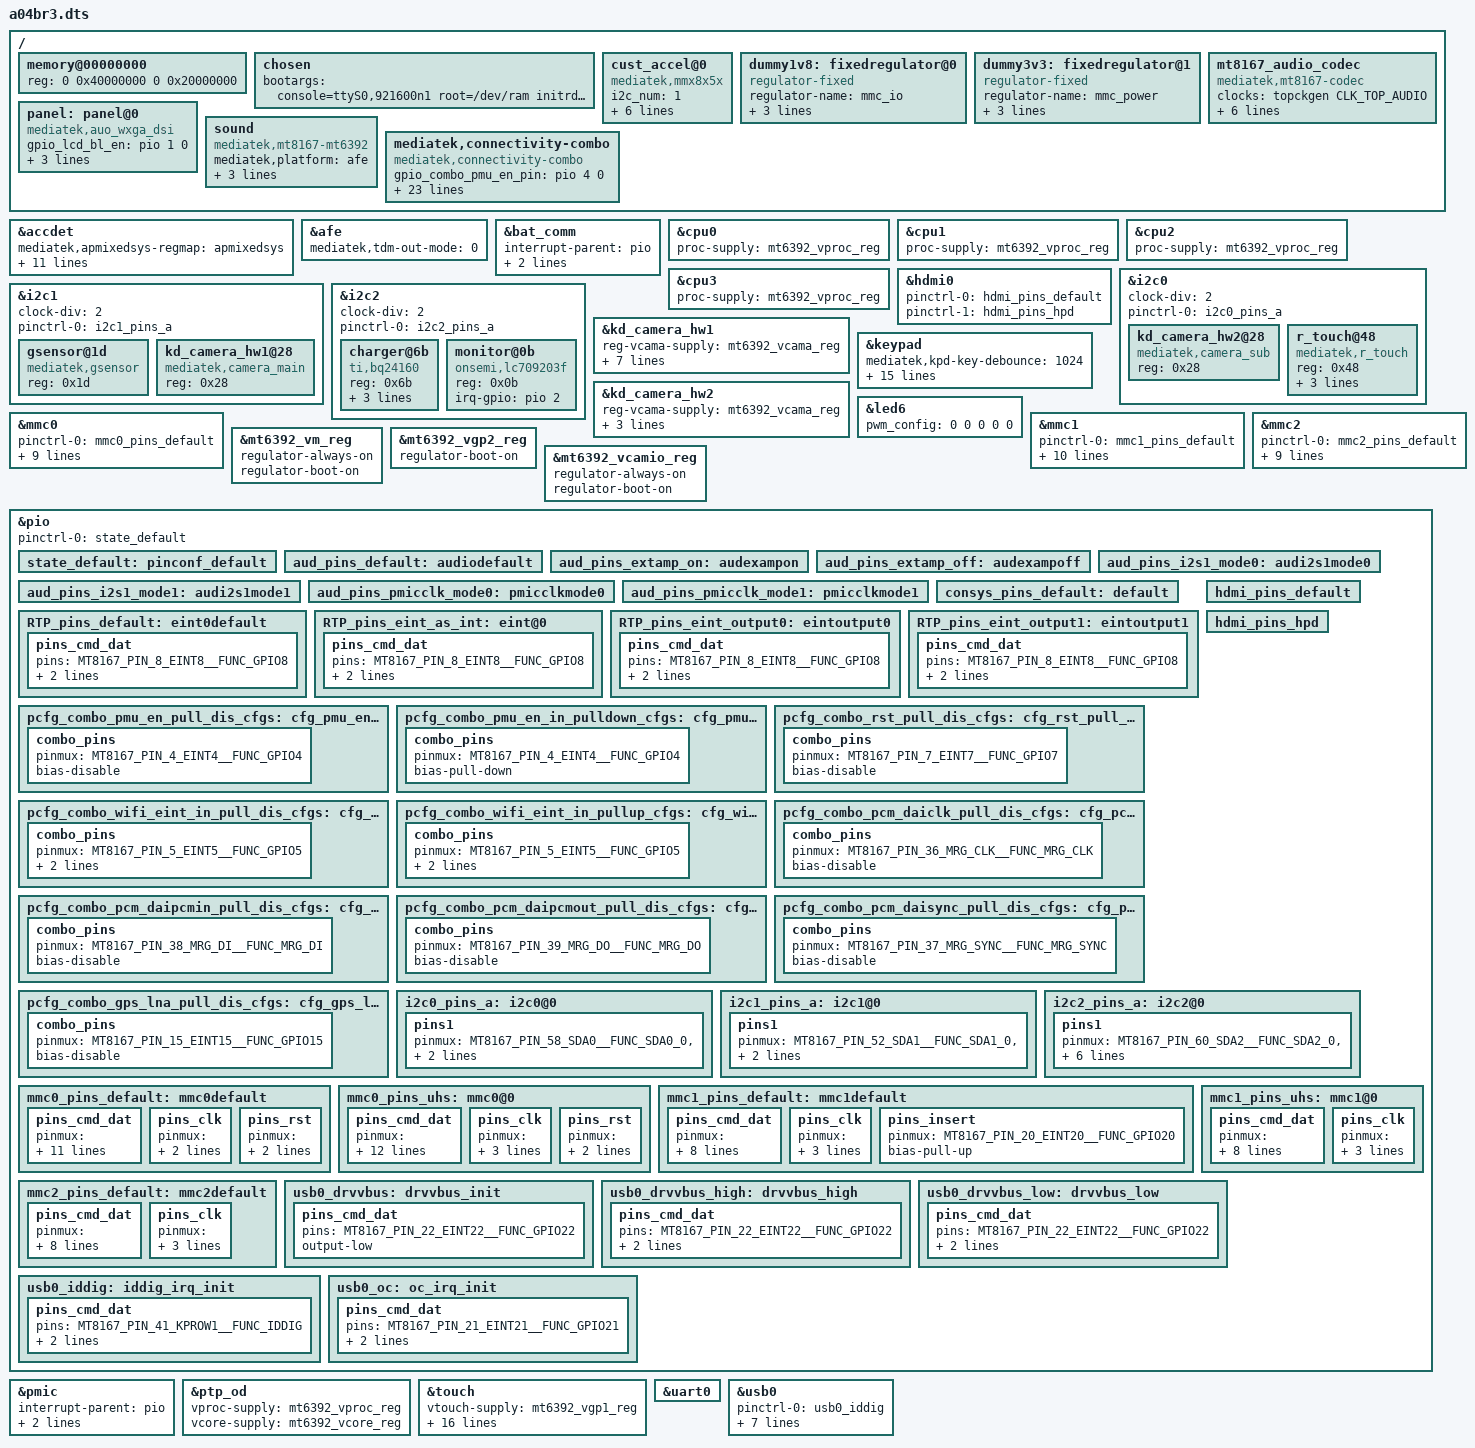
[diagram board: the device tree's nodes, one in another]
/*
 * Copyright (c) 2014-2015 MediaTek Inc.
 *
 * This program is free software; you can redistribute it and/or modify
 * it under the terms of the GNU General Public License version 2 as
 * published by the Free Software Foundation.
 *
 * This program is distributed in the hope that it will be useful,
 * MERCHANTABILITY or FITNESS FOR A PARTICULAR PURPOSE.  See the
 * GNU General Public License for more details.
 */
/*
 * Copyright (C) 2017 SANYO Techno Solutions Tottori Co., Ltd.
 *
 * Changelog:
 *
 * 2018-Feb:  Modify device setting.
 *
 */

/dts-v1/;

#include "mt8167.dtsi"
#include "mt6392.dtsi"

/ {
	memory@00000000 {
		device_type = "memory";
		reg = <0 0x40000000 0 0x20000000>;
	};

	/* chosen */
	chosen {
		bootargs = "console=ttyS0,921600n1 root=/dev/ram initrd=0x44000200,0x200000";
	};

/* sensor standardization */
	cust_accel@0 {
		compatible = "mediatek,mmx8x5x";
/*		compatible = "mediatek,lis2dh";*/
		i2c_num = <1>;
		i2c_addr = <0x1d 0 0 0>;
/*		i2c_addr = <0x18 0 0 0>;*/
		direction = <7>;
		power_id = <0xffff>;
		power_vol = <0>;
		firlen = <0>;
		is_batch_supported = <0>;
	};
/* sensor gpio standization */

	dummy1v8: fixedregulator@0 {
		compatible = "regulator-fixed";
		regulator-name = "mmc_io";
		regulator-min-microvolt = <1800000>;
		regulator-max-microvolt = <1800000>;
		regulator-always-on;
	};

	dummy3v3: fixedregulator@1 {
		compatible = "regulator-fixed";
		regulator-name = "mmc_power";
		regulator-min-microvolt = <3300000>;
		regulator-max-microvolt = <3300000>;
		regulator-always-on;
	};

	mt8167_audio_codec: mt8167_audio_codec {
		compatible = "mediatek,mt8167-codec";
		clocks = <&topckgen CLK_TOP_AUDIO>;
		clock-names = "bus";
		mediatek,afe-regmap = <&afe>;
		mediatek,apmixedsys-regmap = <&apmixedsys>;
		mediatek,pwrap-regmap = <&pwrap>;
		mediatek,speaker-mode = <0>; /* 0(CLASSD) 1(CLASSAB) */
		mediatek,dmic-wire-mode = <1>; /* 0(ONE_WIRE) 1(TWO_WIRE) */
		mediatek,headphone-cap-sel = <1>; /* 0(10UF) 1(22UF) 2(33UF) 3(47UF) */
	};

	panel: panel@0 {
		compatible = "mediatek,auo_wxga_dsi";
		gpio_lcd_bl_en = <&pio 1 0>;
		gpio_lcd_stby = <&pio 67 0>;
		gpio_lcd_rst = <&pio 66 0>;
		reg-lcm-supply = <&mt6392_vgp2_reg>;
		status = "okay";
	};

	sound: sound {
		compatible = "mediatek,mt8167-mt6392";
		mediatek,platform = <&afe>;
		pinctrl-names = "default", "extamp_on", "extamp_off";
		pinctrl-0 = <&aud_pins_default>;
		pinctrl-1 = <&aud_pins_extamp_on>;
		pinctrl-2 = <&aud_pins_extamp_off>;
		status = "okay";
	};

	mediatek,connectivity-combo {
		compatible = "mediatek,connectivity-combo";
		gpio_combo_pmu_en_pin = <&pio 4 0>;	/* GPIO_COMBO_PMU_EN_PIN */
		gpio_combo_rst_pin = <&pio 7 0>;		/* GPIO_COMBO_RST_PIN pin */
		gpio_wifi_eint_pin = <&pio 5 0>;		/* GPIO_WIFI_EINT_PIN */
		gpio_pcm_daiclk_pin = <&pio 36 0>;		/* GPIO_PCM_DAICLK_PIN */
		gpio_pcm_daipcmin_pin = <&pio 38 0>;	/* GPIO_PCM_DAIPCMIN_PIN */
		gpio_pcm_daipcmout_pin = <&pio 39 0>;	/* GPIO_PCM_DAIPCMOUT_PIN */
		gpio_pcm_daisync_pin = <&pio 37 0>;		/* GPIO_PCM_DAISYNC_PIN */
		gpio_gps_lna_pin = <&pio 15 0>;			/* GPIO_GPS_LNA_PIN */
		pinctrl-names = "gpio_pmu_en_pull_dis",
			"gpio_pmu_en_in_pulldown",
			"gpio_rst_pull_dis",
			"gpio_wifi_eint_in_pull_dis",
			"gpio_wifi_eint_in_pullup",
			"gpio_pcm_daiclk_pull_dis",
			"gpio_pcm_daipcmin_pull_dis",
			"gpio_pcm_daipcmout_pull_dis",
			"gpio_pcm_daisync_pull_dis",
			"gpio_gps_lna_pull_dis";
		pinctrl-0 = <&pcfg_combo_pmu_en_pull_dis_cfgs>;
		pinctrl-1 = <&pcfg_combo_pmu_en_in_pulldown_cfgs>;
		pinctrl-2 = <&pcfg_combo_rst_pull_dis_cfgs>;
		pinctrl-3 = <&pcfg_combo_wifi_eint_in_pull_dis_cfgs>;
		pinctrl-4 = <&pcfg_combo_wifi_eint_in_pullup_cfgs>;
		pinctrl-5 = <&pcfg_combo_pcm_daiclk_pull_dis_cfgs>;
		pinctrl-6 = <&pcfg_combo_pcm_daipcmin_pull_dis_cfgs>;
		pinctrl-7 = <&pcfg_combo_pcm_daipcmout_pull_dis_cfgs>;
		pinctrl-8 = <&pcfg_combo_pcm_daisync_pull_dis_cfgs>;
		pinctrl-9 = <&pcfg_combo_gps_lna_pull_dis_cfgs>;
		interrupt-parent = <&pio>;
		interrupts = < 5 IRQ_TYPE_LEVEL_LOW >;	/* WIFI EINT num is 1 active low level-sensitive */
	};
};

&accdet {
	mediatek,apmixedsys-regmap = <&apmixedsys>;
	interrupts-extended = <&sysirq GIC_SPI 152 IRQ_TYPE_LEVEL_LOW>,
				<&pio 19 IRQ_TYPE_LEVEL_LOW>;
	interrupts = <19 IRQ_TYPE_LEVEL_LOW>;
	eint-debounce = <512000>;
	accdet-gpio = <&pio 19 0>;
	accdet-mic-vol = <0>;
	headset-mode-setting = <0x500 0x500 1 0x1f0 0x800 0x800 0x40>;
	accdet-plugout-debounce = <20>;
	/*1:ACC mode, 2:low cost without in bias, 6:low cost with in bias*/
	accdet-mic-mode = <1>;
	status = "okay";
};

&afe {
	/* 0(HDMI) 1(I2S) 2(TDM) */
	mediatek,tdm-out-mode = <0>;
};

&bat_comm {
	interrupt-parent = <&pio>;
	interrupts = <11 IRQ_TYPE_EDGE_RISING>;
	chgled-gpio = <&pio 10 0>;
};


&cpu0 {
	proc-supply = <&mt6392_vproc_reg>;
};

&cpu1 {
	proc-supply = <&mt6392_vproc_reg>;
};

&cpu2 {
	proc-supply = <&mt6392_vproc_reg>;
};

&cpu3 {
	proc-supply = <&mt6392_vproc_reg>;
};

&hdmi0 {
	pinctrl-names = "default", "hdmi_hpd";
	pinctrl-0 = <&hdmi_pins_default>;
	pinctrl-1 = <&hdmi_pins_hpd>;
	status = "okay";
};

&i2c0 {
	clock-div = <2>;
	pinctrl-names = "default";
	pinctrl-0 = <&i2c0_pins_a>;
	status = "okay";

	kd_camera_hw2@28 {
		compatible = "mediatek,camera_sub";
		reg = <0x28>;
	};

	r_touch@48 {
		compatible = "mediatek,r_touch";
		reg = <0x48>;
		interrupt-parent = <&pio>;
		interrupts = <8 IRQ_TYPE_EDGE_FALLING>;
		int-gpio = <&pio 8 0>;

	/*	digipen-gpio = <&pio 0 0>;*/
	};

/*
	wacom_touch@9 {
		compatible = "wacom,i2c";
		reg = <0x09>;
		interrupt-parent = <&pio>;
		interrupts = <3 IRQ_TYPE_EDGE_FALLING>;
		int-gpio = <&pio 3 0>;
		rst-gpio = <&pio 14 0>;
		power-gpio = <&pio 51 0>;
		wacom,swap_xy = <1>;
		wacom,invert_x = <0>;
		wacom,invert_y = <1>;
	};
*/
};

&i2c1 {
	clock-div = <2>;
	pinctrl-names = "default";
	pinctrl-0 = <&i2c1_pins_a>;
	status = "okay";

	gsensor@1d {
		compatible = "mediatek,gsensor";
		reg = <0x1d>;
/*		reg = <0x18>;*/
	};

	kd_camera_hw1@28 {
		compatible = "mediatek,camera_main";
		reg = <0x28>;
	};
};

&i2c2 {
	clock-div = <2>;
	pinctrl-names = "default";
	pinctrl-0 = <&i2c2_pins_a>;
	status = "okay";

	charger@6b {
		compatible = "ti,bq24160";
		reg      = <0x6b>;
		ena-gpio = <&pio 9 0>;
		acdet-gpio = <&pio 35 0>;
		usbdet-gpio = <&pio 34 0>;
	};

	monitor@0b {
		compatible = "onsemi,lc709203f";
		reg      = <0x0b>;
		irq-gpio = <&pio 2 0>;
	};
};

/* Main Cam */
&kd_camera_hw1 {
	reg-vcama-supply = <&mt6392_vcama_reg>;		/* AVDD */
	reg-vcamd-supply = <&mt6392_vcamd_reg>;		/* DVDD */
	reg-vcamio-supply = <&mt6392_vcamio_reg>;	/* DOVDD */
	reg-vcamaf-supply = <&mt6392_vcamaf_reg>;	/* AFVDD */

	cam0_rst = <&pio 49 0>;
	cam0_pdn = <&pio 48 0>;
	cam1_rst = <&pio 100 0>;
	cam1_pdn = <&pio 101 0>;

	status = "okay";
};

/* Sub Cam */
&kd_camera_hw2{
	reg-vcama-supply = <&mt6392_vcama_reg>;		/* AVDD */
	reg-vcamd-supply = <&mt6392_vcamd_reg>;		/* DVDD */
	reg-vcamio-supply = <&mt6392_vcamio_reg>;	/* DOVDD */
	reg-vcamaf-supply = <&mt6392_vcamaf_reg>;	/* AFVDD */

	status = "okay";
};

&keypad {
	mediatek,kpd-key-debounce = <1024>;
	mediatek,kpd-sw-pwrkey = <116>;
	mediatek,kpd-hw-pwrkey = <8>;
	mediatek,kpd-sw-rstkey  = <0>;
	mediatek,kpd-hw-rstkey = <17>;
	mediatek,kpd-use-extend-type = <0>;
	/*HW Keycode [0~71] -> Linux Keycode*/
	mediatek,kpd-hw-map-num = <72>;
	mediatek,kpd-hw-init-map = <115 102 0 0 0 0 0 0 0 0 0 0 0 0 0 0 0 0 0 0 0 0 0 0
			0 0 0 0 0 0 0 0 0 0 0 0 0 0 0 0 0 0 0 0 0 0 0 0
			0 0 0 0 0 0 0 0 0 0 0 0 0 0 0 0 0 0 0 0 0 0 0 0 >;
	mediatek,kpd-pwrkey-eint-gpio = <0>;
	mediatek,kpd-pwkey-gpio-din  = <0>;
	mediatek,kpd-hw-dl-key0 = <0>;
	mediatek,kpd-hw-dl-key1 = <17>;
	mediatek,kpd-hw-dl-key2 = <8>;
	mediatek,kpd-hw-recovery-key = <17>;
	mediatek,kpd-hw-factory-key  = <0>;
};

&led6 {
	pwm_config = <0 0 0 0 0>;
};

&mmc0 {
	pinctrl-names = "default", "state_uhs";
	pinctrl-0 = <&mmc0_pins_default>;
	pinctrl-1 = <&mmc0_pins_uhs>;
	status = "okay";
	bus-width = <8>;
	max-frequency = <200000000>;
	cap-mmc-highspeed;
	mmc-hs200-1_8v;
	cap-mmc-hw-reset;
	vmmc-supply = <&mt6392_vemc3v3_reg>;
	vqmmc-supply = <&mt6392_vio18_reg>;
	non-removable;
};

&mmc1 {
	pinctrl-names = "default", "state_uhs";
	pinctrl-0 = <&mmc1_pins_default>;
	pinctrl-1 = <&mmc1_pins_uhs>;
	status = "okay";
	bus-width = <4>;
	max-frequency = <200000000>;
	cap-sd-highspeed;
	sd-uhs-sdr50;
	sd-uhs-sdr104;
	cd-gpios = <&pio 20 0>;
	cd_level = <1>;
	vmmc-supply = <&mt6392_vmch_reg>;
	vqmmc-supply = <&mt6392_vmc_reg>;
};

&mmc2 {
	pinctrl-names = "default", "state_uhs";
	pinctrl-0 = <&mmc2_pins_default>;
	status = "okay";
	clk_src = <2>;
	host_function = <2>;
	bus-width = <4>;
	max-frequency = <200000000>;
	cap-sd-highspeed;
	sd-uhs-sdr12;
	sd-uhs-sdr25;
	sd-uhs-sdr50;
	sd-uhs-sdr104;
};

&mt6392_vm_reg {
	regulator-always-on;
	regulator-boot-on;
};

&mt6392_vgp2_reg {
	regulator-boot-on;
};

&mt6392_vcamio_reg {
	regulator-always-on;
	regulator-boot-on;
};


&pio {
	pinctrl-names = "default";
	pinctrl-0 = <&state_default>;

	state_default:pinconf_default {
	};

	aud_pins_default: audiodefault {
	};

	aud_pins_extamp_on: audexampon {
	};

	aud_pins_extamp_off: audexampoff {
	};

	aud_pins_i2s1_mode0: audi2s1mode0 {
	};

	aud_pins_i2s1_mode1: audi2s1mode1 {
	};

	aud_pins_pmicclk_mode0: pmicclkmode0 {
	};

	aud_pins_pmicclk_mode1: pmicclkmode1 {
	};

	/* CONSYS GPIO Settings - Start */
	consys_pins_default: default {

	};
	/* CONSYS GPIO Settings - End */

	RTP_pins_default: eint0default {
		pins_cmd_dat {
			pins = <MT8167_PIN_8_EINT8__FUNC_GPIO8>;
			slew-rate = <0>;
			bias-disable;
		};
	};

	RTP_pins_eint_as_int: eint@0 {
		pins_cmd_dat {
			pins = <MT8167_PIN_8_EINT8__FUNC_GPIO8>;
			slew-rate = <0>;
			bias-disable;
		};
	};

	RTP_pins_eint_output0: eintoutput0 {
		pins_cmd_dat {
			pins = <MT8167_PIN_8_EINT8__FUNC_GPIO8>;
			slew-rate = <1>;
			output-low;
		};
	};

	RTP_pins_eint_output1: eintoutput1 {
		pins_cmd_dat {
			pins = <MT8167_PIN_8_EINT8__FUNC_GPIO8>;
			slew-rate = <1>;
			output-high;
		};
	};

	/* ++++++ Connectivity GPIO configs ++++++ */
	pcfg_combo_pmu_en_pull_dis_cfgs:cfg_pmu_en_pull_dis {
		combo_pins {
			pinmux = <MT8167_PIN_4_EINT4__FUNC_GPIO4>;
			bias-disable;
		};
	};

	pcfg_combo_pmu_en_in_pulldown_cfgs:cfg_pmu_en_in_pulldown {
		combo_pins {
			pinmux = <MT8167_PIN_4_EINT4__FUNC_GPIO4>;
			bias-pull-down;
		};
	};

	pcfg_combo_rst_pull_dis_cfgs:cfg_rst_pull_dis {
		combo_pins {
			pinmux = <MT8167_PIN_7_EINT7__FUNC_GPIO7>;
			bias-disable;
		};
	};

	pcfg_combo_wifi_eint_in_pull_dis_cfgs:cfg_wifi_eint_in_pull_dis {
		combo_pins {
			pinmux = <MT8167_PIN_5_EINT5__FUNC_GPIO5>;
			slew-rate = <0>;
			bias-disable;
		};
	};
	pcfg_combo_wifi_eint_in_pullup_cfgs:cfg_wifi_eint_in_pullup {
		combo_pins {
			pinmux = <MT8167_PIN_5_EINT5__FUNC_GPIO5>;
			slew-rate = <0>;
			bias-pull-up = <00>;
		};
	};

	pcfg_combo_pcm_daiclk_pull_dis_cfgs:cfg_pcm_daiclk_pull_dis {
		combo_pins {
			pinmux = <MT8167_PIN_36_MRG_CLK__FUNC_MRG_CLK>;
			bias-disable;
		};
	};

	pcfg_combo_pcm_daipcmin_pull_dis_cfgs:cfg_pcm_daipcmin_pull_dis {
		combo_pins {
			pinmux = <MT8167_PIN_38_MRG_DI__FUNC_MRG_DI>;
			bias-disable;
		};
	};

	pcfg_combo_pcm_daipcmout_pull_dis_cfgs:cfg_pcm_daipcmout_pull_dis {
		combo_pins {
			pinmux = <MT8167_PIN_39_MRG_DO__FUNC_MRG_DO>;
			bias-disable;
		};
	};

	pcfg_combo_pcm_daisync_pull_dis_cfgs:cfg_pcm_daisync_pull_dis {
		combo_pins {
			pinmux = <MT8167_PIN_37_MRG_SYNC__FUNC_MRG_SYNC>;
			bias-disable;
		};
	};

	pcfg_combo_gps_lna_pull_dis_cfgs:cfg_gps_lna_pull_dis {
		combo_pins {
			pinmux = <MT8167_PIN_15_EINT15__FUNC_GPIO15>;
			bias-disable;
		};
	};

	/* ------ Connectivity GPIO configs ------ */


	hdmi_pins_default: hdmi_pins_default {
	};

	hdmi_pins_hpd: hdmi_pins_hpd {
	};

	i2c0_pins_a: i2c0@0 {
		pins1 {
			pinmux = <MT8167_PIN_58_SDA0__FUNC_SDA0_0>,
				 <MT8167_PIN_59_SCL0__FUNC_SCL0_0>;
			bias-disable;
		};
	};

	i2c1_pins_a: i2c1@0 {
		pins1 {
			pinmux = <MT8167_PIN_52_SDA1__FUNC_SDA1_0>,
				 <MT8167_PIN_53_SCL1__FUNC_SCL1_0>;
			bias-disable;
		};
	};

	i2c2_pins_a: i2c2@0 {
		pins1 {
			pinmux = <MT8167_PIN_60_SDA2__FUNC_SDA2_0>,
				 <MT8167_PIN_61_SCL2__FUNC_SCL2_0>,
				 <MT8167_PIN_3_EINT3__FUNC_GPIO3>,
				 <MT8167_PIN_9_EINT9__FUNC_GPIO9>,
				 <MT8167_PIN_10_EINT10__FUNC_GPIO10>,
				 <MT8167_PIN_11_EINT11__FUNC_GPIO11>;
			bias-disable;
		};
	};

	mmc0_pins_default: mmc0default {
		pins_cmd_dat {
			pinmux = <MT8167_PIN_120_MSDC0_DAT0__FUNC_MSDC0_DAT0>,
				<MT8167_PIN_119_MSDC0_DAT1__FUNC_MSDC0_DAT1>,
				<MT8167_PIN_118_MSDC0_DAT2__FUNC_MSDC0_DAT2>,
				<MT8167_PIN_117_MSDC0_DAT3__FUNC_MSDC0_DAT3>,
				<MT8167_PIN_113_MSDC0_DAT4__FUNC_MSDC0_DAT4>,
				<MT8167_PIN_112_MSDC0_DAT5__FUNC_MSDC0_DAT5>,
				<MT8167_PIN_111_MSDC0_DAT6__FUNC_MSDC0_DAT6>,
				<MT8167_PIN_110_MSDC0_DAT7__FUNC_MSDC0_DAT7>,
				<MT8167_PIN_115_MSDC0_CMD__FUNC_MSDC0_CMD>;
			input-enable;
			bias-pull-up;
		};

		pins_clk {
			pinmux = <MT8167_PIN_116_MSDC0_CLK__FUNC_MSDC0_CLK>;
			bias-pull-down;
		};

		pins_rst {
			pinmux = <MT8167_PIN_114_MSDC0_RSTB__FUNC_MSDC0_RSTB>;
			bias-pull-up;
		};
	};

	mmc0_pins_uhs: mmc0@0{
		pins_cmd_dat {
			pinmux = <MT8167_PIN_120_MSDC0_DAT0__FUNC_MSDC0_DAT0>,
				<MT8167_PIN_119_MSDC0_DAT1__FUNC_MSDC0_DAT1>,
				<MT8167_PIN_118_MSDC0_DAT2__FUNC_MSDC0_DAT2>,
				<MT8167_PIN_117_MSDC0_DAT3__FUNC_MSDC0_DAT3>,
				<MT8167_PIN_113_MSDC0_DAT4__FUNC_MSDC0_DAT4>,
				<MT8167_PIN_112_MSDC0_DAT5__FUNC_MSDC0_DAT5>,
				<MT8167_PIN_111_MSDC0_DAT6__FUNC_MSDC0_DAT6>,
				<MT8167_PIN_110_MSDC0_DAT7__FUNC_MSDC0_DAT7>,
				<MT8167_PIN_115_MSDC0_CMD__FUNC_MSDC0_CMD>;
			input-enable;
			drive-strength = <MTK_DRIVE_6mA>;
			bias-pull-up = <MTK_PUPD_SET_R1R0_01>;
		};

		pins_clk {
			pinmux = <MT8167_PIN_116_MSDC0_CLK__FUNC_MSDC0_CLK>;
			drive-strength = <MTK_DRIVE_8mA>;
			bias-pull-down = <MTK_PUPD_SET_R1R0_10>;
		};

		pins_rst {
			pinmux = <MT8167_PIN_114_MSDC0_RSTB__FUNC_MSDC0_RSTB>;
			bias-pull-up;
		};
	};

	mmc1_pins_default: mmc1default {
		pins_cmd_dat {
			pinmux = <MT8167_PIN_106_MSDC1_DAT0__FUNC_MSDC1_DAT0>,
				<MT8167_PIN_107_MSDC1_DAT1__FUNC_MSDC1_DAT1>,
				<MT8167_PIN_108_MSDC1_DAT2__FUNC_MSDC1_DAT2>,
				<MT8167_PIN_109_MSDC1_DAT3__FUNC_MSDC1_DAT3>,
				<MT8167_PIN_104_MSDC1_CMD__FUNC_MSDC1_CMD>;
			input-enable;
			drive-strength = <MTK_DRIVE_6mA>;
			bias-pull-up = <MTK_PUPD_SET_R1R0_01>;
		};

		pins_clk {
			pinmux = <MT8167_PIN_105_MSDC1_CLK__FUNC_MSDC1_CLK>;
			drive-strength = <MTK_DRIVE_6mA>;
			bias-pull-down = <MTK_PUPD_SET_R1R0_10>;
		};

		pins_insert {
			pinmux = <MT8167_PIN_20_EINT20__FUNC_GPIO20>;
			bias-pull-up;
		};
	};

	mmc1_pins_uhs: mmc1@0 {
		pins_cmd_dat {
			pinmux = <MT8167_PIN_106_MSDC1_DAT0__FUNC_MSDC1_DAT0>,
				<MT8167_PIN_107_MSDC1_DAT1__FUNC_MSDC1_DAT1>,
				<MT8167_PIN_108_MSDC1_DAT2__FUNC_MSDC1_DAT2>,
				<MT8167_PIN_109_MSDC1_DAT3__FUNC_MSDC1_DAT3>,
				<MT8167_PIN_104_MSDC1_CMD__FUNC_MSDC1_CMD>;
			input-enable;
			drive-strength = <MTK_DRIVE_6mA>;
			bias-pull-up = <MTK_PUPD_SET_R1R0_01>;
		};

		pins_clk {
			pinmux = <MT8167_PIN_105_MSDC1_CLK__FUNC_MSDC1_CLK>;
			drive-strength = <MTK_DRIVE_8mA>;
			bias-pull-down = <MTK_PUPD_SET_R1R0_10>;
		};
	};

	mmc2_pins_default: mmc2default {
		pins_cmd_dat {
			pinmux = <MT8167_PIN_70_MSDC2_DAT0__FUNC_MSDC2_DAT0>,
				<MT8167_PIN_71_MSDC2_DAT1__FUNC_MSDC2_DAT1>,
				<MT8167_PIN_72_MSDC2_DAT2__FUNC_MSDC2_DAT2>,
				<MT8167_PIN_73_MSDC2_DAT3__FUNC_MSDC2_DAT3>,
				<MT8167_PIN_68_MSDC2_CMD__FUNC_MSDC2_CMD>;
			input-enable;
			drive-strength = <MTK_DRIVE_8mA>;
			bias-pull-up = <MTK_PUPD_SET_R1R0_01>;
		};

		pins_clk {
			pinmux = <MT8167_PIN_69_MSDC2_CLK__FUNC_MSDC2_CLK>;
			drive-strength = <MTK_DRIVE_8mA>;
			bias-pull-down = <MTK_PUPD_SET_R1R0_10>;
		};
	};

/* USB GPIO start */
	usb0_drvvbus: drvvbus_init {
		pins_cmd_dat {
			pins = <MT8167_PIN_22_EINT22__FUNC_GPIO22>;
			output-low;
		};
	};

	usb0_drvvbus_high: drvvbus_high {
		pins_cmd_dat {
			pins = <MT8167_PIN_22_EINT22__FUNC_GPIO22>;
			slew-rate = <1>;
			output-high;
		};
	};

	usb0_drvvbus_low: drvvbus_low {
		pins_cmd_dat {
			pins = <MT8167_PIN_22_EINT22__FUNC_GPIO22>;
			slew-rate = <1>;
			output-low;
		};
	};

	usb0_iddig: iddig_irq_init {
		pins_cmd_dat {
			pins = <MT8167_PIN_41_KPROW1__FUNC_IDDIG>;
			slew-rate = <0>;
			bias-pull-up = <00>;
		};
	};

	usb0_oc: oc_irq_init {
		pins_cmd_dat {
			pins = <MT8167_PIN_21_EINT21__FUNC_GPIO21>;
			slew-rate = <0>;
			bias-pull-up = <00>;
		};
	};
/* USB GPIO end */
};

&pmic {
	interrupt-parent = <&pio>;
	interrupts = <28 IRQ_TYPE_LEVEL_HIGH>;
	interrupt-controller;
	#interrupt-cells = <2>;
};

&ptp_od {
	vproc-supply = <&mt6392_vproc_reg>;
	vcore-supply = <&mt6392_vcore_reg>;
};

&touch {
	vtouch-supply = <&mt6392_vgp1_reg>;
	tpd-resolution = <1280 800>;
	use-tpd-button = <0>;
	tpd-key-num = <0>;
	tpd-key-local= <139 172 158 0>;
	tpd-key-dim-local = <60 850 50 30 180 850 50 30 300 850 50 30 420 850 50 30>;
	tpd-max-touch-num = <1>;
	tpd-filter-enable = <0>;
	tpd-filter-pixel-density = <124>;
	tpd-filter-custom-prameters = <0 0 0 0 0 0 0 0 0 0 0 0>;
	tpd-filter-custom-speed = <0 0 0>;
	pinctrl-names = "default", "state_eint_as_int", "state_eint_output0", "state_eint_output1";

	pinctrl-0 = <&RTP_pins_default>;
	pinctrl-1 = <&RTP_pins_eint_as_int>;
	pinctrl-2 = <&RTP_pins_eint_output0>;
	pinctrl-3 = <&RTP_pins_eint_output1>;

	status = "okay";
};

&uart0 {
	status="okay";
};

&usb0 {
	pinctrl-names = "iddig_irq_init", "drvvbus_init", "drvvbus_low", "drvvbus_high", "oc_irq_init";
	pinctrl-0 = <&usb0_iddig>;
	pinctrl-1 = <&usb0_drvvbus>;
	pinctrl-2 = <&usb0_drvvbus_low>;
	pinctrl-3 = <&usb0_drvvbus_high>;
	pinctrl-4 = <&usb0_oc>;
	usb-power-supply = <&mt6392_vusb_reg>;
	status = "okay";
	drvvbus_gpio = <&pio 22 0>;
	usb_detect_gpio = <&pio 34 0>;
};
